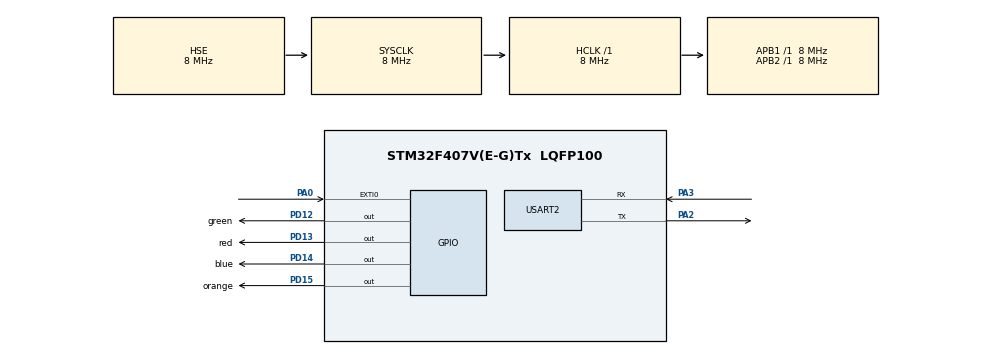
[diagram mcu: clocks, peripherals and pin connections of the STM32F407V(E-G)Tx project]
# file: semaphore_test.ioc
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Mcu.Family=STM32F4
RCC.PLLSourceVirtual=RCC_PLLSOURCE_HSE
PD12.GPIO_Label=green
PH0-OSC_IN.Signal=RCC_OSC_IN
RCC.CortexFreq_Value=8000000
FREERTOS.Tasks01=NormalTask,0,128,StartNormaTask,Default,NULL,Dynamic,NULL,NULL;HighTask,1,128,StartHighTask,Default,NULL,Dynamic,NULL,NULL;LowTask,-1,128,StartLowTask,Default,NULL,Dynamic,NULL,NULL
FREERTOS.BinarySemaphores01=BinSem,Dynamic,NULL
PD15.GPIO_Label=orange
PA0-WKUP.GPIO_ModeDefaultEXTI=GPIO_MODE_IT_RISING
RCC.SYSCLKSource=RCC_SYSCLKSOURCE_HSE
ProjectManager.StackSize=0x400
PA0-WKUP.Signal=GPXTI0
PD13.Signal=GPIO_Output
PA3.Mode=Asynchronous
ProjectManager.TargetToolchain=STM32CubeIDE
RCC.HCLKFreq_Value=8000000
RCC.APB2TimFreq_Value=8000000
RCC.LSE_VALUE=32768
RCC.AHBFreq_Value=8000000
PH0-OSC_IN.Mode=HSE-External-Oscillator
RCC.HSE_VALUE=8000000
board=custom
RCC.VCOOutputFreq_Value=96000000
RCC.APB2Freq_Value=8000000
VP_SYS_VS_tim1.Mode=TIM1
PH1-OSC_OUT.Signal=RCC_OSC_OUT
PD14.GPIO_Label=blue
VP_FREERTOS_VS_CMSIS_V1.Mode=CMSIS_V1
Mcu.Name=STM32F407V(E-G)Tx
PA2.Signal=USART2_TX
PD14.Signal=GPIO_Output
PH1-OSC_OUT.Mode=HSE-External-Oscillator
RCC.48MHZClocksFreq_Value=24000000
NVIC.EXTI0_IRQn=true\:5\:0\:false\:false\:true\:false\:true\:true
RCC.SYSCLKFreq_VALUE=8000000
PD13.GPIO_Label=red
Mcu.Package=LQFP100
NVIC.TimeBase=TIM1_UP_TIM10_IRQn
USART2.VirtualMode=VM_ASYNC
PD12.Signal=GPIO_Output
NVIC.TimeBaseIP=TIM1
ProjectManager.HeapSize=0x200
NVIC.TIM1_UP_TIM10_IRQn=true\:0\:0\:false\:false\:true\:false\:false\:true
RCC.HSI_VALUE=16000000
NVIC.PriorityGroup=NVIC_PRIORITYGROUP_4
RCC.APB1TimFreq_Value=8000000
PA2.Mode=Asynchronous
RCC.APB1Freq_Value=8000000
PD15.Signal=GPIO_Output
PA3.Signal=USART2_RX

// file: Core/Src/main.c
/* USER CODE BEGIN Header */
/**
  ******************************************************************************
  * @file           : main.c
  * @brief          : Main program body
  ******************************************************************************
  * @attention
  *
  * <h2><center>&copy; Copyright (c) 2021 STMicroelectronics.
  * All rights reserved.</center></h2>
  *
  * This software component is licensed by ST under BSD 3-Clause license,
  * the "License"; You may not use this file except in compliance with the
  * License. You may obtain a copy of the License at:
  *                        opensource.org/licenses/BSD-3-Clause
  *
  ******************************************************************************
  */
/* USER CODE END Header */
#include "main.h"
#include "cmsis_os.h"

/* USER CODE BEGIN PM */
volatile uint16_t flag=0;
/* USER CODE END PM */

UART_HandleTypeDef huart2;

osThreadId NormalTaskHandle;
osThreadId HighTaskHandle;
osThreadId LowTaskHandle;
osSemaphoreId BinSemHandle;

void SystemClock_Config(void);
static void MX_GPIO_Init(void);
static void MX_USART2_UART_Init(void);
void StartNormaTask(void const * argument);
void StartHighTask(void const * argument);
//void StartLowTask(void const * argument);

int main(void)
{

  /* MCU Configuration--------------------------------------------------------*/

  /* Reset of all peripherals, Initializes the Flash interface and the Systick. */
  HAL_Init();

  /* Configure the system clock */
  SystemClock_Config();

  /* Initialize all configured peripherals */
  MX_GPIO_Init();
  MX_USART2_UART_Init();

  /* Create the semaphores(s) */
  /* definition and creation of BinSem */
  osSemaphoreDef(BinSem);
  BinSemHandle = osSemaphoreCreate(osSemaphore(BinSem), 1);

  /* Create the thread(s) */
  /* definition and creation of NormalTask */
  osThreadDef(NormalTask, StartNormaTask, osPriorityNormal, 0, 128);
  NormalTaskHandle = osThreadCreate(osThread(NormalTask), NULL);

  /* definition and creation of HighTask */
  osThreadDef(HighTask, StartHighTask, osPriorityAboveNormal, 0, 128);
  HighTaskHandle = osThreadCreate(osThread(HighTask), NULL);

  /* definition and creation of LowTask */
 // osThreadDef(LowTask, StartLowTask, osPriorityBelowNormal, 0, 128);
//  LowTaskHandle = osThreadCreate(osThread(LowTask), NULL);

  /* Start scheduler */
  osKernelStart();

  /* We should never get here as control is now taken by the scheduler */
  /* Infinite loop */
  while (1)
  {

  }
}

void SystemClock_Config(void)
{
  RCC_OscInitTypeDef RCC_OscInitStruct = {0};
  RCC_ClkInitTypeDef RCC_ClkInitStruct = {0};

  /** Configure the main internal regulator output voltage
  */
  __HAL_RCC_PWR_CLK_ENABLE();
  __HAL_PWR_VOLTAGESCALING_CONFIG(PWR_REGULATOR_VOLTAGE_SCALE1);
  /** Initializes the RCC Oscillators according to the specified parameters
  * in the RCC_OscInitTypeDef structure.
  */
  RCC_OscInitStruct.OscillatorType = RCC_OSCILLATORTYPE_HSE;
  RCC_OscInitStruct.HSEState = RCC_HSE_ON;
  RCC_OscInitStruct.PLL.PLLState = RCC_PLL_NONE;
  if (HAL_RCC_OscConfig(&RCC_OscInitStruct) != HAL_OK)
  {
    Error_Handler();
  }
  /** Initializes the CPU, AHB and APB buses clocks
  */
  RCC_ClkInitStruct.ClockType = RCC_CLOCKTYPE_HCLK|RCC_CLOCKTYPE_SYSCLK
                              |RCC_CLOCKTYPE_PCLK1|RCC_CLOCKTYPE_PCLK2;
  RCC_ClkInitStruct.SYSCLKSource = RCC_SYSCLKSOURCE_HSE;
  RCC_ClkInitStruct.AHBCLKDivider = RCC_SYSCLK_DIV1;
  RCC_ClkInitStruct.APB1CLKDivider = RCC_HCLK_DIV1;
  RCC_ClkInitStruct.APB2CLKDivider = RCC_HCLK_DIV1;

  if (HAL_RCC_ClockConfig(&RCC_ClkInitStruct, FLASH_LATENCY_0) != HAL_OK)
  {
    Error_Handler();
  }
}

static void MX_USART2_UART_Init(void)
{

  huart2.Instance = USART2;
  huart2.Init.BaudRate = 115200;
  huart2.Init.WordLength = UART_WORDLENGTH_8B;
  huart2.Init.StopBits = UART_STOPBITS_1;
  huart2.Init.Parity = UART_PARITY_NONE;
  huart2.Init.Mode = UART_MODE_TX_RX;
  huart2.Init.HwFlowCtl = UART_HWCONTROL_NONE;
  huart2.Init.OverSampling = UART_OVERSAMPLING_16;
  if (HAL_UART_Init(&huart2) != HAL_OK)
  {
    Error_Handler();
  }

}
int ret =0;

static void MX_GPIO_Init(void)
{
  GPIO_InitTypeDef GPIO_InitStruct = {0};

  /* GPIO Ports Clock Enable */
  __HAL_RCC_GPIOH_CLK_ENABLE();
  __HAL_RCC_GPIOA_CLK_ENABLE();
  __HAL_RCC_GPIOD_CLK_ENABLE();

  /*Configure GPIO pin Output Level */
  HAL_GPIO_WritePin(GPIOD, green_Pin|red_Pin|blue_Pin|orange_Pin, GPIO_PIN_RESET);

  /*Configure GPIO pin : PA0 */
  GPIO_InitStruct.Pin = GPIO_PIN_0;
  GPIO_InitStruct.Mode = GPIO_MODE_IT_RISING;
  GPIO_InitStruct.Pull = GPIO_NOPULL;
  HAL_GPIO_Init(GPIOA, &GPIO_InitStruct);

  /*Configure GPIO pins : green_Pin red_Pin blue_Pin orange_Pin */
  GPIO_InitStruct.Pin = green_Pin|red_Pin|blue_Pin|orange_Pin;
  GPIO_InitStruct.Mode = GPIO_MODE_OUTPUT_PP;
  GPIO_InitStruct.Pull = GPIO_NOPULL;
  GPIO_InitStruct.Speed = GPIO_SPEED_FREQ_LOW;
  HAL_GPIO_Init(GPIOD, &GPIO_InitStruct);

  /* EXTI interrupt init*/
  HAL_NVIC_SetPriority(EXTI0_IRQn, 5, 0);
  HAL_NVIC_EnableIRQ(EXTI0_IRQn);

}

void StartNormaTask(void const * argument)
{
  /* USER CODE BEGIN 5 */
  /* Infinite loop */
  for(;;)
  {

	  char *str1= "Entered Normaltask\n";
	 HAL_UART_Transmit(&huart2, (uint8_t *)str1, strlen(str1), 100);

//	 while(HAL_GPIO_ReadPin(GPIOA, GPIO_PIN_0));

	  ret = osSemaphoreWait(BinSemHandle, osWaitForever);

	 char *str3= "semaphore has been aquired by medium task\n";
	  HAL_UART_Transmit(&huart2, (uint8_t *)str3, strlen(str3), 100);

	//  while(!(HAL_GPIO_ReadPin(button_GPIO_Port, button_Pin))); //wait for pin to go low

	   char *str2= "leaving Normaltask and releasing the semaphore\n";
	   HAL_UART_Transmit(&huart2, (uint8_t *)str2, strlen(str2), 100);

	//  	   osSemaphoreRelease(BinSemHandle);
           osDelay(500);
  }
  /* USER CODE END 5 */
}

void StartHighTask(void const * argument)
{
  /* USER CODE BEGIN StartHighTask */
  /* Infinite loop */
  for(;;)
  {
	  char *str1= "Entered Hightask\n";
//	  HAL_UART_Transmit(&huart2, (uint8_t *)str1, strlen(str1), 100);

	     char *str2= "leaving Hightask\n";
	// 	 HAL_UART_Transmit(&huart2, (uint8_t *)str2, strlen(str2), 100);

      osDelay(500);
  }
  /* USER CODE END StartHighTask */
}

/*void StartLowTask(void const * argument)
{

  for(;;)
  {
    osDelay(1);
  }

}*/

 /**
  * @brief  Period elapsed callback in non blocking mode
  * @note   This function is called  when TIM1 interrupt took place, inside
  * HAL_TIM_IRQHandler(). It makes a direct call to HAL_IncTick() to increment
  * a global variable "uwTick" used as application time base.
  * @param  htim : TIM handle
  * @retval None
  */
void HAL_TIM_PeriodElapsedCallback(TIM_HandleTypeDef *htim)
{
  if (htim->Instance == TIM1) {
    HAL_IncTick();
  }
}
void HAL_GPIO_EXTI_Callback(uint16_t GPIO_Pin)
{
		osSemaphoreRelease(BinSemHandle);

}

void Error_Handler(void)
{
  __disable_irq();
  while (1)
  {
  }
}

/************************ (C) COPYRIGHT STMicroelectronics *****END OF FILE****/
